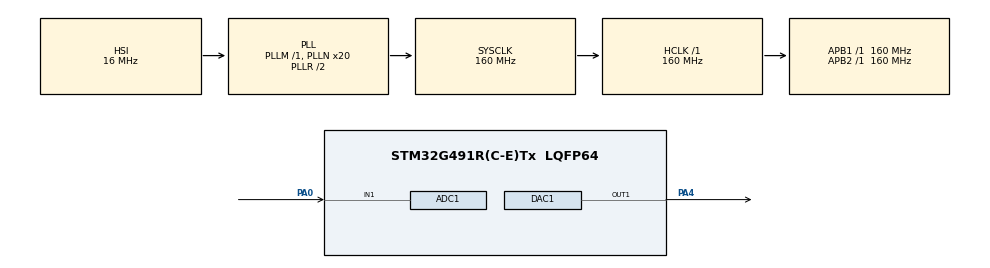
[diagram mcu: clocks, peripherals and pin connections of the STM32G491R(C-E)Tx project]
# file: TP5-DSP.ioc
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ADC1.Channel-0\#ChannelRegularConversion=ADC_CHANNEL_1
ADC1.NbrOfConversionFlag=1
ADC1.OffsetNumber-0\#ChannelRegularConversion=ADC_OFFSET_NONE
ADC1.Rank-0\#ChannelRegularConversion=1
ADC1.SamplingTime-0\#ChannelRegularConversion=ADC_SAMPLETIME_2CYCLES_5
ADC1.master=1
Mcu.Family=STM32G4
Mcu.Name=STM32G491R(C-E)Tx
Mcu.Package=LQFP64
NVIC.ADC1_2_IRQn=true\:0\:0\:false\:false\:true\:true\:true\:true
NVIC.PriorityGroup=NVIC_PRIORITYGROUP_4
NVIC.TIM2_IRQn=true\:0\:0\:false\:false\:true\:true\:true\:true
NVIC.TIM6_DAC_IRQn=true\:0\:0\:false\:false\:true\:true\:true\:true
PA0.Mode=IN1-Single-Ended
PA0.Signal=ADC1_IN1
PA13.GPIO_Label=T_SWDIO
PA13.Mode=Serial_Wire
PA13.Signal=SYS_JTMS-SWDIO
PA14.GPIO_Label=T_SWCLK
PA14.Mode=Serial_Wire
PA14.Signal=SYS_JTCK-SWCLK
PA2.GPIO_Label=LPUART1_TX [STLINKV3E_VCP_RX]
PA2.Signal=LPUART1_TX
PA3.GPIO_Label=LPUART1_RX [STLINKV3E_VCP_TX]
PA3.Signal=LPUART1_RX
PA4.Signal=COMP_DAC11_group
PB3.GPIO_Label=T_SWO
PB3.Signal=SYS_JTDO-SWO
PC14-OSC32_IN.GPIO_Label=RCC_OSC32_IN
PC14-OSC32_IN.Signal=RCC_OSC32_IN
PC15-OSC32_OUT.GPIO_Label=RCC_OSC32_OUT
PC15-OSC32_OUT.Signal=RCC_OSC32_OUT
PF0-OSC_IN.GPIO_Label=RCC_OSC_IN
PF0-OSC_IN.Signal=RCC_OSC_IN
PF1-OSC_OUT.GPIO_Label=RCC_OSC_OUT
PF1-OSC_OUT.Signal=RCC_OSC_OUT
ProjectManager.HeapSize=0x200
ProjectManager.StackSize=0x400
ProjectManager.TargetToolchain=STM32CubeIDE
RCC.ADC12Freq_Value=160000000
RCC.ADC345Freq_Value=160000000
RCC.AHBFreq_Value=160000000
RCC.APB1Freq_Value=160000000
RCC.APB1TimFreq_Value=160000000
RCC.APB2Freq_Value=160000000
RCC.APB2TimFreq_Value=160000000
RCC.CortexFreq_Value=160000000
RCC.EXTERNAL_CLOCK_VALUE=12288000
RCC.HCLKFreq_Value=160000000
RCC.HSE_VALUE=24000000
RCC.HSI48_VALUE=48000000
RCC.HSI_VALUE=16000000
RCC.LSE_VALUE=32768
RCC.PLLN=20
RCC.RTCClockSelection=RCC_RTCCLKSOURCE_LSE
RCC.SYSCLKFreq_VALUE=160000000
RCC.SYSCLKSource=RCC_SYSCLKSOURCE_PLLCLK
RCC.USBFreq_Value=48000000
RCC.VCOOutputFreq_Value=320000000
SH.COMP_DAC11_group.0=DAC1_OUT1,DAC_OUT1
TIM2.PeriodNoDither=9999
TIM2.Prescaler=1
VP_SYS_VS_DBSignals.Mode=DisableDeadBatterySignals
VP_TIM2_VS_ClockSourceINT.Mode=Internal
board=NUCLEO-G491RE

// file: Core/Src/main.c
/* USER CODE BEGIN Header */
/**
 ******************************************************************************
 * @file           : main.c
 * @brief          : Main program body
 ******************************************************************************
 * @attention
 *
 * Copyright (c) 2026 STMicroelectronics.
 * All rights reserved.
 *
 * This software is licensed under terms that can be found in the LICENSE file
 * in the root directory of this software component.
 * If no LICENSE file comes with this software, it is provided AS-IS.
 *
 ******************************************************************************
 */
/* USER CODE END Header */
#include "main.h"
#include "adc.h"
#include "dac.h"
#include "tim.h"
#include "gpio.h"

/* USER CODE BEGIN Includes */
#include "FIR.h"
#include "iir_sos.h"
#include "iir_coeffs.h"
#include <math.h>
/* USER CODE END Includes */

/* USER CODE BEGIN PD */
/* Elegir uno de los cuatro y recompilar. */
#define FILTRO_FIR_PASABAJO     0
#define FILTRO_FIR_PASAALTO     1
#define FILTRO_IIR_PASABANDA    2
#define FILTRO_IIR_RECHAZABANDA 3
#ifndef FILTRO_ACTIVO
#define FILTRO_ACTIVO FILTRO_IIR_PASABANDA
#endif
#if FILTRO_ACTIVO < 0 || FILTRO_ACTIVO > 3
#error "FILTRO_ACTIVO invalido"
#endif
#if IIR_FS_HZ != 8000
#error "Ajustar TIM2 al cambiar la frecuencia de diseno"
#endif
#define ADC_VREF 3.3f
/* Ajustar al offset real del generador (por defecto 1.65 V). */
#define OFFSET_ENTRADA_V 1.65f
#define OFFSET_SALIDA_V  1.65f
/* USER CODE END PD */

/* USER CODE BEGIN PV */
volatile uint32_t muestra = 0;
volatile float conv = 0.0f; /* Salida antes de sumar offset y limitar al DAC. */
volatile uint32_t dac_value = 0;
volatile uint32_t muestras_procesadas = 0;
volatile uint32_t errores_adc = 0;
volatile uint32_t saturaciones_dac = 0;
volatile uint32_t fallos_numericos = 0;
volatile uint32_t ciclos_filtro_max = 0;
#if FILTRO_ACTIVO == FILTRO_IIR_PASABANDA
static IIR_State estado[IIR_PASABANDA_SECTIONS] = {0};
#elif FILTRO_ACTIVO == FILTRO_IIR_RECHAZABANDA
static IIR_State estado[IIR_RECHAZABANDA_SECTIONS] = {0};
#else
static float input_signal[N_FIR] = {0};
#endif
/* USER CODE END PV */

void SystemClock_Config(void);

/* USER CODE BEGIN 0 */
static float filtrar_muestra(float x)
{
#if FILTRO_ACTIVO == FILTRO_IIR_PASABANDA
    return iir_process(x, iir_pasabanda, estado, IIR_PASABANDA_SECTIONS);
#elif FILTRO_ACTIVO == FILTRO_IIR_RECHAZABANDA
    return iir_process(x, iir_rechazabanda, estado, IIR_RECHAZABANDA_SECTIONS);
#else
    for (int i = N_FIR - 1; i > 0; --i)
        input_signal[i] = input_signal[i - 1];
    input_signal[0] = x;
    float y = 0.0f;
    for (int i = 0; i < N_FIR; ++i) {
#if FILTRO_ACTIVO == FILTRO_FIR_PASABAJO
        y += fir_pasabajo[i] * input_signal[i];
#else
        y += fir_pasaalto[i] * input_signal[i];
#endif
    }
    return y;
#endif
}
/* USER CODE END 0 */

int main(void)
{

  /* MCU Configuration--------------------------------------------------------*/

  /* Reset of all peripherals, Initializes the Flash interface and the Systick. */
  HAL_Init();

  /* Configure the system clock */
  SystemClock_Config();

  /* Initialize all configured peripherals */
  MX_GPIO_Init();
  MX_ADC1_Init();
  MX_DAC1_Init();
  MX_TIM2_Init();
  /* USER CODE BEGIN 2 */
    /* Iniciar el reloj de muestreo al final, con ADC y DAC preparados. */
    if (HAL_ADCEx_Calibration_Start(&hadc1, ADC_SINGLE_ENDED) != HAL_OK)
        Error_Handler();
    if (HAL_DAC_Start(&hdac1, DAC_CHANNEL_1) != HAL_OK)
        Error_Handler();
    HAL_DAC_SetValue(&hdac1, DAC_CHANNEL_1, DAC_ALIGN_12B_R, 2048);
    CoreDebug->DEMCR |= CoreDebug_DEMCR_TRCENA_Msk;
    DWT->CYCCNT = 0;
    DWT->CTRL |= DWT_CTRL_CYCCNTENA_Msk;
    if (HAL_TIM_Base_Start_IT(&htim2) != HAL_OK)
        Error_Handler();
  /* USER CODE END 2 */

  /* Infinite loop */
    while (1) {

    /* USER CODE BEGIN 3 */
        /* ADC -> filtro -> DAC se procesa una vez por conversion en el callback. */
    }
  /* USER CODE END 3 */
}

void SystemClock_Config(void)
{
  RCC_OscInitTypeDef RCC_OscInitStruct = {0};
  RCC_ClkInitTypeDef RCC_ClkInitStruct = {0};

  /** Configure the main internal regulator output voltage
  */
  HAL_PWREx_ControlVoltageScaling(PWR_REGULATOR_VOLTAGE_SCALE1_BOOST);

  /** Initializes the RCC Oscillators according to the specified parameters
  * in the RCC_OscInitTypeDef structure.
  */
  RCC_OscInitStruct.OscillatorType = RCC_OSCILLATORTYPE_HSI;
  RCC_OscInitStruct.HSIState = RCC_HSI_ON;
  RCC_OscInitStruct.HSICalibrationValue = RCC_HSICALIBRATION_DEFAULT;
  RCC_OscInitStruct.PLL.PLLState = RCC_PLL_ON;
  RCC_OscInitStruct.PLL.PLLSource = RCC_PLLSOURCE_HSI;
  RCC_OscInitStruct.PLL.PLLM = RCC_PLLM_DIV1;
  RCC_OscInitStruct.PLL.PLLN = 20;
  RCC_OscInitStruct.PLL.PLLP = RCC_PLLP_DIV2;
  RCC_OscInitStruct.PLL.PLLQ = RCC_PLLQ_DIV2;
  RCC_OscInitStruct.PLL.PLLR = RCC_PLLR_DIV2;
  if (HAL_RCC_OscConfig(&RCC_OscInitStruct) != HAL_OK)
  {
    Error_Handler();
  }

  /** Initializes the CPU, AHB and APB buses clocks
  */
  RCC_ClkInitStruct.ClockType = RCC_CLOCKTYPE_HCLK|RCC_CLOCKTYPE_SYSCLK
                              |RCC_CLOCKTYPE_PCLK1|RCC_CLOCKTYPE_PCLK2;
  RCC_ClkInitStruct.SYSCLKSource = RCC_SYSCLKSOURCE_PLLCLK;
  RCC_ClkInitStruct.AHBCLKDivider = RCC_SYSCLK_DIV1;
  RCC_ClkInitStruct.APB1CLKDivider = RCC_HCLK_DIV1;
  RCC_ClkInitStruct.APB2CLKDivider = RCC_HCLK_DIV1;

  if (HAL_RCC_ClockConfig(&RCC_ClkInitStruct, FLASH_LATENCY_4) != HAL_OK)
  {
    Error_Handler();
  }
}

/* USER CODE BEGIN 4 */
void HAL_TIM_PeriodElapsedCallback(TIM_HandleTypeDef *htim)
{
    if (htim->Instance == TIM2) {
        if (HAL_ADC_Start_IT(&hadc1) != HAL_OK)
            ++errores_adc;
    }
}

void HAL_ADC_ConvCpltCallback(ADC_HandleTypeDef *hadc)
{
    if (hadc->Instance != ADC1)
        return;
    uint32_t inicio = DWT->CYCCNT;
    muestra = HAL_ADC_GetValue(hadc);
    float x = (float)muestra * ADC_VREF / 4095.0f - OFFSET_ENTRADA_V;
    conv = filtrar_muestra(x);
    float salida_v = conv + OFFSET_SALIDA_V;
    if (!isfinite(salida_v)) {
        ++fallos_numericos;
        salida_v = OFFSET_SALIDA_V;
    }
    if (salida_v < 0.0f) {
        salida_v = 0.0f;
        ++saturaciones_dac;
    } else if (salida_v > ADC_VREF) {
        salida_v = ADC_VREF;
        ++saturaciones_dac;
    }
    /* Limitar en float ANTES de convertir al entero sin signo. */
    dac_value = (uint32_t)(salida_v * 4095.0f / ADC_VREF + 0.5f);
    HAL_DAC_SetValue(&hdac1, DAC_CHANNEL_1, DAC_ALIGN_12B_R, dac_value);
    ++muestras_procesadas;
    uint32_t ciclos = DWT->CYCCNT - inicio;
    if (ciclos > ciclos_filtro_max)
        ciclos_filtro_max = ciclos;
}

void HAL_ADC_ErrorCallback(ADC_HandleTypeDef *hadc)
{
    if (hadc->Instance == ADC1)
        ++errores_adc;
}
/* USER CODE END 4 */

void Error_Handler(void)
{
	__disable_irq();
	while (1) {
	}
}
